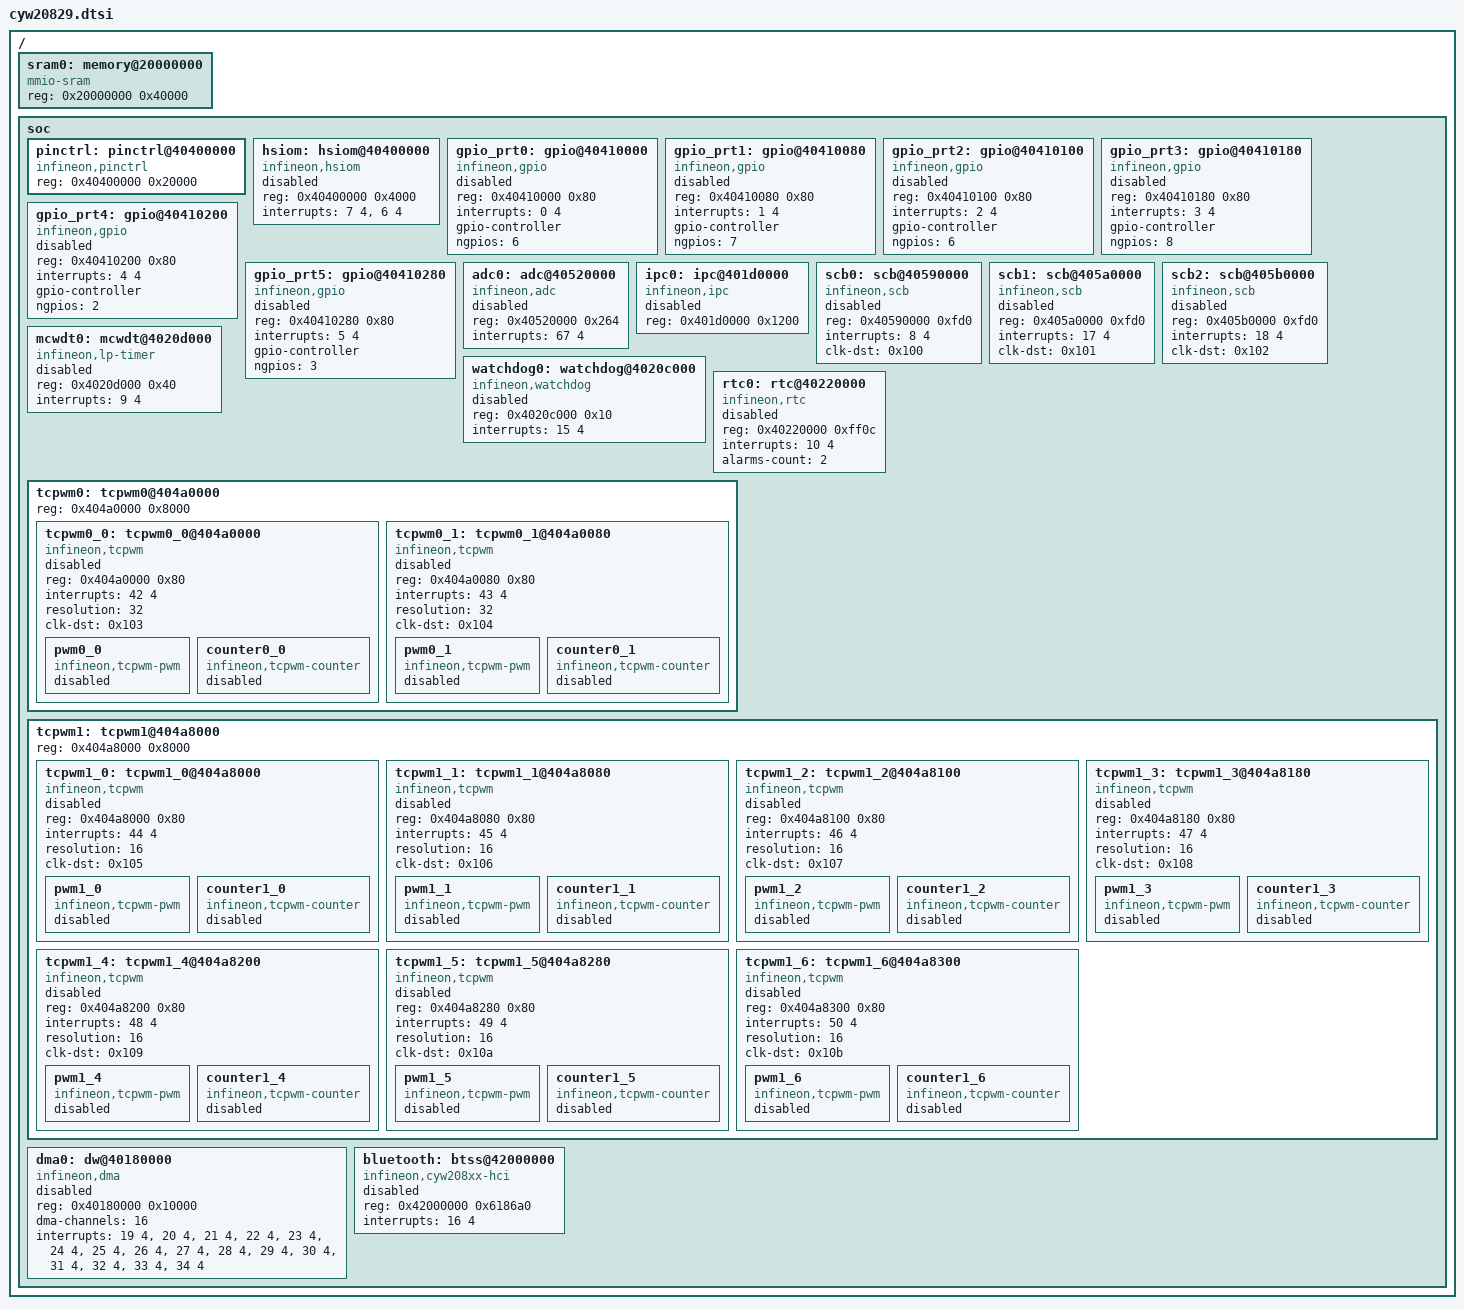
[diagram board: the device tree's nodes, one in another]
/*
 * Copyright (c) 2026 Infineon Technologies AG,
 * or an affiliate of Infineon Technologies AG.
 *
 * SPDX-License-Identifier: Apache-2.0
 */

#include <mem.h>
#include "cyw20829.cm33.dtsi"

/ {
	sram0: memory@20000000 {
		compatible = "mmio-sram";
		reg = <0x20000000 0x40000>;
	};

	soc {
		pinctrl: pinctrl@40400000 {
			compatible = "infineon,pinctrl";
			reg = <0x40400000 0x20000>;
		};

		hsiom: hsiom@40400000 {
			compatible = "infineon,hsiom";
			reg = <0x40400000 0x4000>;
			interrupts = <7 4>, <6 4>;
			status = "disabled";
		};

		gpio_prt0: gpio@40410000 {
			compatible = "infineon,gpio";
			reg = <0x40410000 0x80>;
			interrupts = <0 4>;
			gpio-controller;
			ngpios = <6>;
			status = "disabled";
			#gpio-cells = <2>;
		};

		gpio_prt1: gpio@40410080 {
			compatible = "infineon,gpio";
			reg = <0x40410080 0x80>;
			interrupts = <1 4>;
			gpio-controller;
			ngpios = <7>;
			status = "disabled";
			#gpio-cells = <2>;
		};

		gpio_prt2: gpio@40410100 {
			compatible = "infineon,gpio";
			reg = <0x40410100 0x80>;
			interrupts = <2 4>;
			gpio-controller;
			ngpios = <6>;
			status = "disabled";
			#gpio-cells = <2>;
		};

		gpio_prt3: gpio@40410180 {
			compatible = "infineon,gpio";
			reg = <0x40410180 0x80>;
			interrupts = <3 4>;
			gpio-controller;
			ngpios = <8>;
			status = "disabled";
			#gpio-cells = <2>;
		};

		gpio_prt4: gpio@40410200 {
			compatible = "infineon,gpio";
			reg = <0x40410200 0x80>;
			interrupts = <4 4>;
			gpio-controller;
			ngpios = <2>;
			status = "disabled";
			#gpio-cells = <2>;
		};

		gpio_prt5: gpio@40410280 {
			compatible = "infineon,gpio";
			reg = <0x40410280 0x80>;
			interrupts = <5 4>;
			gpio-controller;
			ngpios = <3>;
			status = "disabled";
			#gpio-cells = <2>;
		};

		adc0: adc@40520000 {
			compatible = "infineon,adc";
			reg = <0x40520000 0x264>;
			interrupts = <67 4>;
			status = "disabled";
			#io-channel-cells = <1>;
		};

		ipc0: ipc@401d0000 {
			compatible = "infineon,ipc";
			reg = <0x401d0000 0x1200>;
			status = "disabled";
			#ipc-config-cells = <3>;
		};

		scb0: scb@40590000 {
			compatible = "infineon,scb";
			reg = <0x40590000 0xfd0>;
			interrupts = <8 4>;
			clk-dst = <0x100>;
			status = "disabled";
		};

		scb1: scb@405a0000 {
			compatible = "infineon,scb";
			reg = <0x405a0000 0xfd0>;
			interrupts = <17 4>;
			clk-dst = <0x101>;
			status = "disabled";
		};

		scb2: scb@405b0000 {
			compatible = "infineon,scb";
			reg = <0x405b0000 0xfd0>;
			interrupts = <18 4>;
			clk-dst = <0x102>;
			status = "disabled";
		};

		watchdog0: watchdog@4020c000 {
			compatible = "infineon,watchdog";
			reg = <0x4020c000 0x10>;
			interrupts = <15 4>;
			status = "disabled";
		};

		mcwdt0: mcwdt@4020d000 {
			compatible = "infineon,lp-timer";
			reg = <0x4020d000 0x40>;
			interrupts = <9 4>;
			status = "disabled";
		};

		rtc0: rtc@40220000 {
			compatible = "infineon,rtc";
			reg = <0x40220000 0xff0c>;
			interrupts = <10 4>;
			alarms-count = <2>;
			status = "disabled";
		};

		tcpwm0: tcpwm0@404a0000 {
			reg = <0x404a0000 0x8000>;
			#address-cells = <1>;
			#size-cells = <1>;

			tcpwm0_0: tcpwm0_0@404a0000 {
				compatible = "infineon,tcpwm";
				reg = <0x404a0000 0x80>;
				interrupts = <42 4>;
				resolution = <32>;
				clk-dst = <0x103>;
				status = "disabled";

				pwm0_0: pwm0_0 {
					compatible = "infineon,tcpwm-pwm";
					#pwm-cells = <3>;
					status = "disabled";
				};

				counter0_0: counter0_0 {
					compatible = "infineon,tcpwm-counter";
					status = "disabled";
				};
			};

			tcpwm0_1: tcpwm0_1@404a0080 {
				compatible = "infineon,tcpwm";
				reg = <0x404a0080 0x80>;
				interrupts = <43 4>;
				resolution = <32>;
				clk-dst = <0x104>;
				status = "disabled";

				pwm0_1: pwm0_1 {
					compatible = "infineon,tcpwm-pwm";
					#pwm-cells = <3>;
					status = "disabled";
				};

				counter0_1: counter0_1 {
					compatible = "infineon,tcpwm-counter";
					status = "disabled";
				};
			};
		};

		tcpwm1: tcpwm1@404a8000 {
			reg = <0x404a8000 0x8000>;
			#address-cells = <1>;
			#size-cells = <1>;

			tcpwm1_0: tcpwm1_0@404a8000 {
				compatible = "infineon,tcpwm";
				reg = <0x404a8000 0x80>;
				interrupts = <44 4>;
				resolution = <16>;
				clk-dst = <0x105>;
				status = "disabled";

				pwm1_0: pwm1_0 {
					compatible = "infineon,tcpwm-pwm";
					#pwm-cells = <3>;
					status = "disabled";
				};

				counter1_0: counter1_0 {
					compatible = "infineon,tcpwm-counter";
					status = "disabled";
				};
			};

			tcpwm1_1: tcpwm1_1@404a8080 {
				compatible = "infineon,tcpwm";
				reg = <0x404a8080 0x80>;
				interrupts = <45 4>;
				resolution = <16>;
				clk-dst = <0x106>;
				status = "disabled";

				pwm1_1: pwm1_1 {
					compatible = "infineon,tcpwm-pwm";
					#pwm-cells = <3>;
					status = "disabled";
				};

				counter1_1: counter1_1 {
					compatible = "infineon,tcpwm-counter";
					status = "disabled";
				};
			};

			tcpwm1_2: tcpwm1_2@404a8100 {
				compatible = "infineon,tcpwm";
				reg = <0x404a8100 0x80>;
				interrupts = <46 4>;
				resolution = <16>;
				clk-dst = <0x107>;
				status = "disabled";

				pwm1_2: pwm1_2 {
					compatible = "infineon,tcpwm-pwm";
					#pwm-cells = <3>;
					status = "disabled";
				};

				counter1_2: counter1_2 {
					compatible = "infineon,tcpwm-counter";
					status = "disabled";
				};
			};

			tcpwm1_3: tcpwm1_3@404a8180 {
				compatible = "infineon,tcpwm";
				reg = <0x404a8180 0x80>;
				interrupts = <47 4>;
				resolution = <16>;
				clk-dst = <0x108>;
				status = "disabled";

				pwm1_3: pwm1_3 {
					compatible = "infineon,tcpwm-pwm";
					#pwm-cells = <3>;
					status = "disabled";
				};

				counter1_3: counter1_3 {
					compatible = "infineon,tcpwm-counter";
					status = "disabled";
				};
			};

			tcpwm1_4: tcpwm1_4@404a8200 {
				compatible = "infineon,tcpwm";
				reg = <0x404a8200 0x80>;
				interrupts = <48 4>;
				resolution = <16>;
				clk-dst = <0x109>;
				status = "disabled";

				pwm1_4: pwm1_4 {
					compatible = "infineon,tcpwm-pwm";
					#pwm-cells = <3>;
					status = "disabled";
				};

				counter1_4: counter1_4 {
					compatible = "infineon,tcpwm-counter";
					status = "disabled";
				};
			};

			tcpwm1_5: tcpwm1_5@404a8280 {
				compatible = "infineon,tcpwm";
				reg = <0x404a8280 0x80>;
				interrupts = <49 4>;
				resolution = <16>;
				clk-dst = <0x10a>;
				status = "disabled";

				pwm1_5: pwm1_5 {
					compatible = "infineon,tcpwm-pwm";
					#pwm-cells = <3>;
					status = "disabled";
				};

				counter1_5: counter1_5 {
					compatible = "infineon,tcpwm-counter";
					status = "disabled";
				};
			};

			tcpwm1_6: tcpwm1_6@404a8300 {
				compatible = "infineon,tcpwm";
				reg = <0x404a8300 0x80>;
				interrupts = <50 4>;
				resolution = <16>;
				clk-dst = <0x10b>;
				status = "disabled";

				pwm1_6: pwm1_6 {
					compatible = "infineon,tcpwm-pwm";
					#pwm-cells = <3>;
					status = "disabled";
				};

				counter1_6: counter1_6 {
					compatible = "infineon,tcpwm-counter";
					status = "disabled";
				};
			};
		};

		dma0: dw@40180000 {
			#dma-cells = <1>;
			compatible = "infineon,dma";
			reg = <0x40180000 0x10000>;
			dma-channels = <16>;
			interrupts = <19 4>, /* CH0 */
				     <20 4>, /* CH1 */
				     <21 4>, /* CH2 */
				     <22 4>, /* CH3 */
				     <23 4>, /* CH4 */
				     <24 4>, /* CH5 */
				     <25 4>, /* CH6 */
				     <26 4>, /* CH7 */
				     <27 4>, /* CH8 */
				     <28 4>, /* CH9 */
				     <29 4>, /* CH10 */
				     <30 4>, /* CH11 */
				     <31 4>, /* CH12 */
				     <32 4>, /* CH13 */
				     <33 4>, /* CH14 */
				     <34 4>; /* CH15 */
			status = "disabled";
		};

		bluetooth: btss@42000000 {
			compatible = "infineon,cyw208xx-hci";
			reg = <0x42000000 0x6186a0>;
			interrupts = <16 4>;
			status = "disabled";
		};
	};
};
